# HT32F275x register map
File version: 1.1
CPU: CM3 r2p0, little endian, no MPU, no FPU, 4 interrupt priority bits
Registers are 32-bit, read-write, reset 0x0 unless marked. A register's access mark holds for its fields unless they carry their own. Offsets are from the block's base; [hi:lo] are bit positions; {n}, {i} and the like mark numbered series.

## SCI
Base 0x40043000
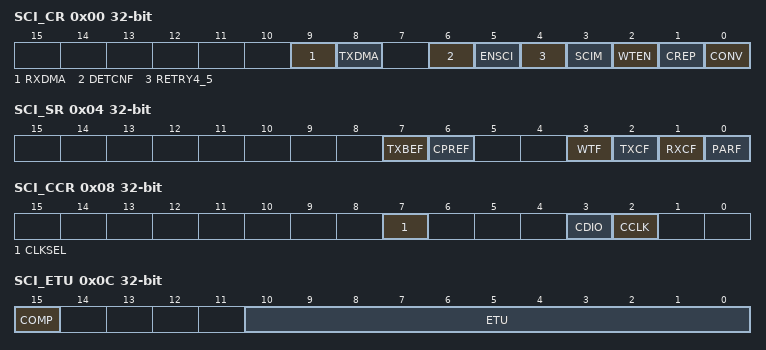
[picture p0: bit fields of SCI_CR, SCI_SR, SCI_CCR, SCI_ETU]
0x00 SCI_CR
  [9] RXDMA, [8] TXDMA, [6] DETCNF, [5] ENSCI, [4] RETRY4_5, [3] SCIM, [2] WTEN, [1] CREP, [0] CONV
0x04 SCI_SR
  [7] TXBEF, [6] CPREF, [3] WTF, [2] TXCF, [1] RXCF, [0] PARF
0x08 SCI_CCR
  [7] CLKSEL, [3] CDIO, [2] CCLK
0x0C SCI_ETU
  [15] COMP, [10:0] ETU
0x10 SCI_GT
  [8:0] GT
0x14 SCI_WT
  [23:0] WT
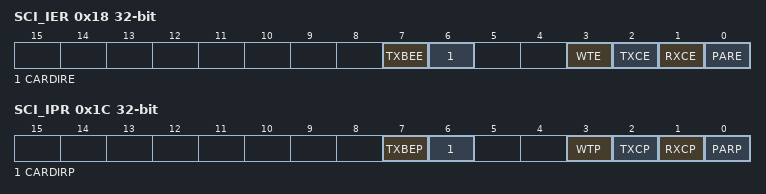
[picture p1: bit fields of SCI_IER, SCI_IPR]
0x18 SCI_IER
  [7] TXBEE, [6] CARDIRE, [3] WTE, [2] TXCE, [1] RXCE, [0] PARE
0x1C SCI_IPR
  [7] TXBEP, [6] CARDIRP, [3] WTP, [2] TXCP, [1] RXCP, [0] PARP
0x20 SCI_TXB
  [7:0] TB
0x24 SCI_RXB
  [7:0] RB
0x28 SCI_PSC
  [5:0] PSC

## USB
Base 0x4004E000
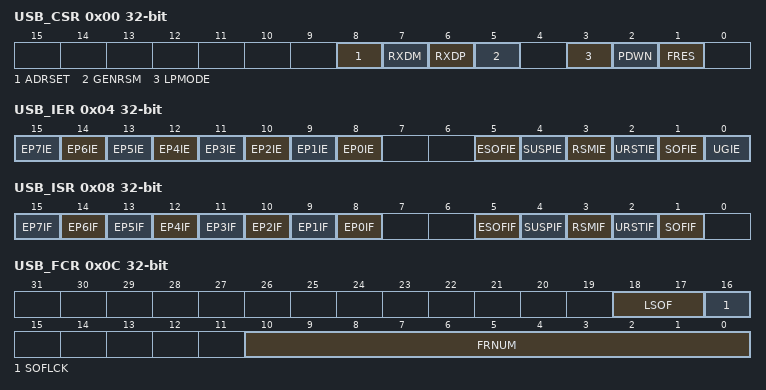
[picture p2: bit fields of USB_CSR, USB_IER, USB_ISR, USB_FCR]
0x00 USB_CSR
  [8] ADRSET, [7] RXDM, [6] RXDP, [5] GENRSM, [3] LPMODE, [2] PDWN, [1] FRES
0x04 USB_IER
  [n+8] EP{n}IE (n=0..7), [5] ESOFIE, [4] SUSPIE, [3] RSMIE, [2] URSTIE, [1] SOFIE, [0] UGIE
0x08 USB_ISR
  [n+8] EP{n}IF (n=0..7), [5] ESOFIF, [4] SUSPIF, [3] RSMIF, [2] URSTIF, [1] SOFIF
0x0C USB_FCR
  [18:17] LSOF, [16] SOFLCK, [10:0] FRNUM
0x10 USB_DEVAR
  [6:0] DEVA
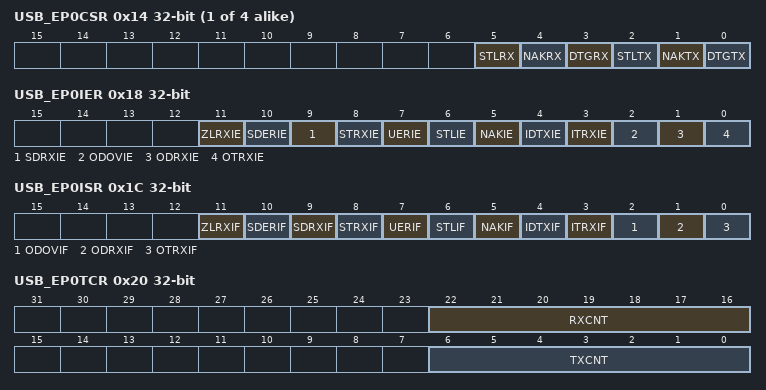
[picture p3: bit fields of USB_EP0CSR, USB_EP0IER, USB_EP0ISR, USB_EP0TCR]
{0x14+0x14*i} USB_EP{i}CSR (i=0..3)
  [5] STLRX, [4] NAKRX, [3] DTGRX, [2] STLTX, [1] NAKTX, [0] DTGTX
0x18 USB_EP0IER
  [11] ZLRXIE, [10] SDERIE, [9] SDRXIE, [8] STRXIE, [7] UERIE, [6] STLIE, [5] NAKIE, [4] IDTXIE, [3] ITRXIE, [2] ODOVIE, [1] ODRXIE, [0] OTRXIE
0x1C USB_EP0ISR
  [11] ZLRXIF, [10] SDERIF, [9] SDRXIF, [8] STRXIF, [7] UERIF, [6] STLIF, [5] NAKIF, [4] IDTXIF, [3] ITRXIF, [2] ODOVIF, [1] ODRXIF, [0] OTRXIF
0x20 USB_EP0TCR
  [22:16] RXCNT, [6:0] TXCNT
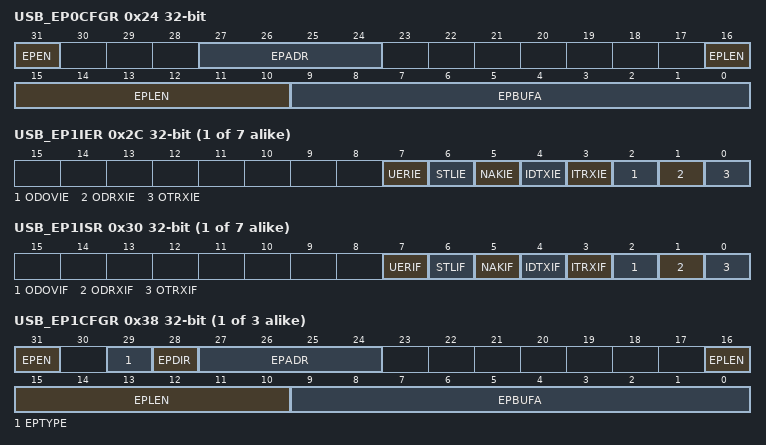
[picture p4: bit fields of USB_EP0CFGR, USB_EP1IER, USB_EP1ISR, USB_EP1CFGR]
0x24 USB_EP0CFGR
  [31] EPEN, [27:24] EPADR, [16:10] EPLEN, [9:0] EPBUFA
{0x18+0x14*i} USB_EP{i}IER (i=1..7)
  [7] UERIE, [6] STLIE, [5] NAKIE, [4] IDTXIE, [3] ITRXIE, [2] ODOVIE, [1] ODRXIE, [0] OTRXIE
{0x1C+0x14*i} USB_EP{i}ISR (i=1..7)
  [7] UERIF, [6] STLIF, [5] NAKIF, [4] IDTXIF, [3] ITRXIF, [2] ODOVIF, [1] ODRXIF, [0] OTRXIF
{0x20+0x14*i} USB_EP{i}TCR (i=1..3)
  [8:0] TCNT
{0x24+0x14*i} USB_EP{i}CFGR (i=1..3)
  [31] EPEN, [29] EPTYPE, [28] EPDIR, [27:24] EPADR, [16:10] EPLEN, [9:0] EPBUFA
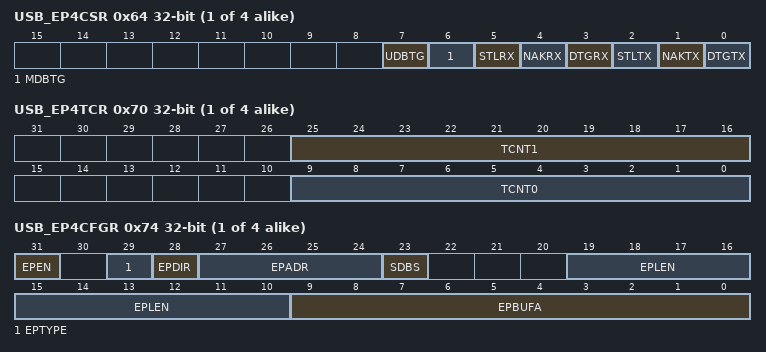
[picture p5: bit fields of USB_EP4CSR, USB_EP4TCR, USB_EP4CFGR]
{0x14+0x14*i} USB_EP{i}CSR (i=4..7)
  [7] UDBTG, [6] MDBTG, [5] STLRX, [4] NAKRX, [3] DTGRX, [2] STLTX, [1] NAKTX, [0] DTGTX
{0x20+0x14*i} USB_EP{i}TCR (i=4..7)
  [25:16] TCNT1, [9:0] TCNT0
{0x24+0x14*i} USB_EP{i}CFGR (i=4..7)
  [31] EPEN, [29] EPTYPE, [28] EPDIR, [27:24] EPADR, [23] SDBS, [19:10] EPLEN, [9:0] EPBUFA

## PDMA
Base 0x40090000
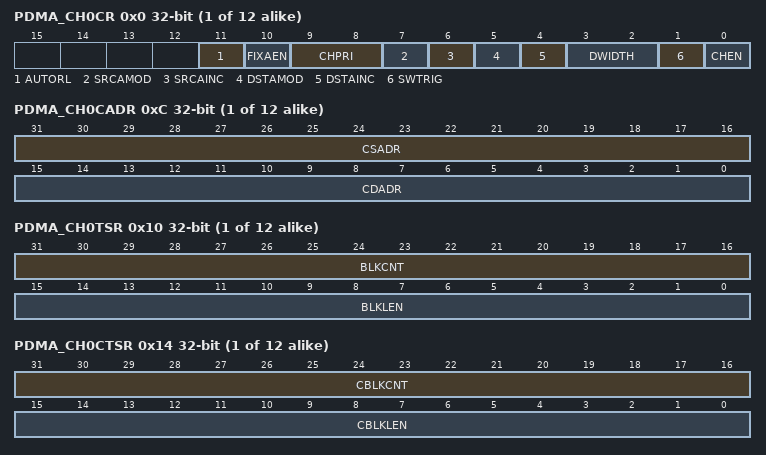
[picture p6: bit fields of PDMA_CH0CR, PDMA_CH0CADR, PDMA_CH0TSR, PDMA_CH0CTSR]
{0x0+0x18*i} PDMA_CH{i}CR (i=0..11)
  [11] AUTORL, [10] FIXAEN, [9:8] CHPRI, [7] SRCAMOD, [6] SRCAINC, [5] DSTAMOD, [4] DSTAINC, [3:2] DWIDTH, [1] SWTRIG, [0] CHEN
{0x4+0x18*i} PDMA_CH{i}SADR (i=0..11)
  [31:0] SADR
{0x8+0x18*i} PDMA_CH{i}DADR (i=0..11)
  [31:0] DADR
{0xC+0x18*i} PDMA_CH{i}CADR (i=0..11)
  [31:16] CSADR, [15:0] CDADR
{0x10+0x18*i} PDMA_CH{i}TSR (i=0..11)
  [31:16] BLKCNT, [15:0] BLKLEN
{0x14+0x18*i} PDMA_CH{i}CTSR (i=0..11)
  [31:16] CBLKCNT, [15:0] CBLKLEN
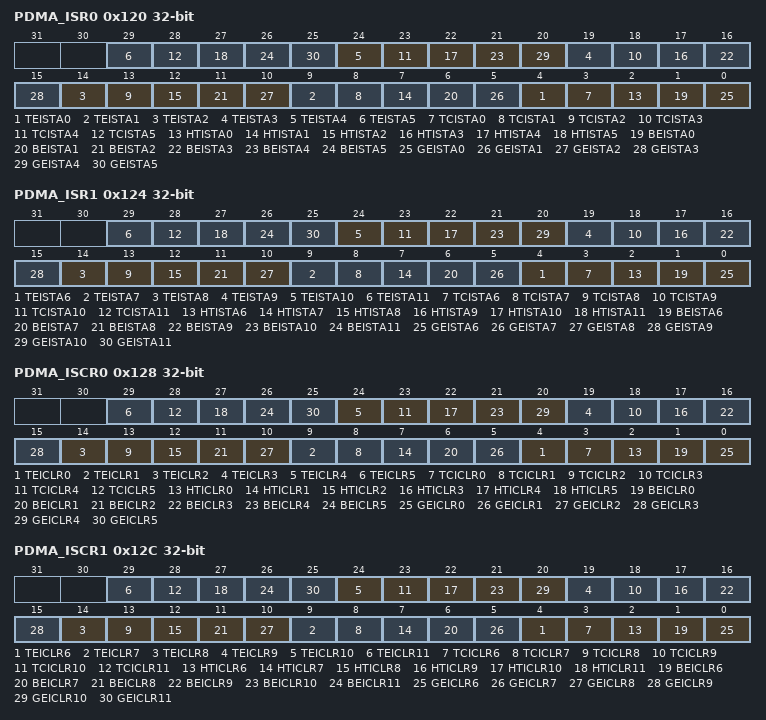
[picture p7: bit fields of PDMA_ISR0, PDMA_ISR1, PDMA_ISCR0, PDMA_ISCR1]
0x120 PDMA_ISR0
  [5n+4] TEISTA{n} (n=0..5), [5n+3] TCISTA{n} (n=0..5), [5n+2] HTISTA{n} (n=0..5), [5n+1] BEISTA{n} (n=0..5), [5n] GEISTA{n} (n=0..5)
0x124 PDMA_ISR1
  [5n-26] TEISTA{n} (n=6..11), [5n-27] TCISTA{n} (n=6..11), [5n-28] HTISTA{n} (n=6..11), [5n-29] BEISTA{n} (n=6..11), [5n-30] GEISTA{n} (n=6..11)
0x128 PDMA_ISCR0
  [5n+4] TEICLR{n} (n=0..5), [5n+3] TCICLR{n} (n=0..5), [5n+2] HTICLR{n} (n=0..5), [5n+1] BEICLR{n} (n=0..5), [5n] GEICLR{n} (n=0..5)
0x12C PDMA_ISCR1
  [5n-26] TEICLR{n} (n=6..11), [5n-27] TCICLR{n} (n=6..11), [5n-28] HTICLR{n} (n=6..11), [5n-29] BEICLR{n} (n=6..11), [5n-30] GEICLR{n} (n=6..11)
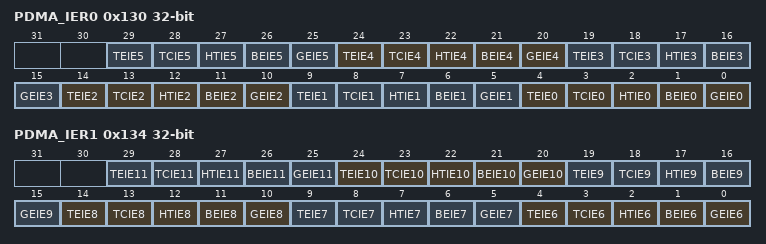
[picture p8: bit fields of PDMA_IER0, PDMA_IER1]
0x130 PDMA_IER0
  [5n+4] TEIE{n} (n=0..5), [5n+3] TCIE{n} (n=0..5), [5n+2] HTIE{n} (n=0..5), [5n+1] BEIE{n} (n=0..5), [5n] GEIE{n} (n=0..5)
0x134 PDMA_IER1
  [5n-26] TEIE{n} (n=6..11), [5n-27] TCIE{n} (n=6..11), [5n-28] HTIE{n} (n=6..11), [5n-29] BEIE{n} (n=6..11), [5n-30] GEIE{n} (n=6..11)

## CSIF
Base 0x400CC000
0x00 CSIF_ENR
  [31] CSIF_EN
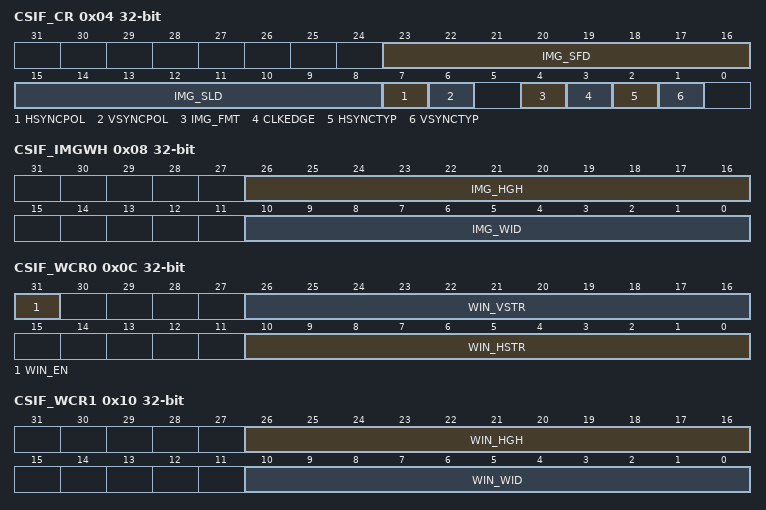
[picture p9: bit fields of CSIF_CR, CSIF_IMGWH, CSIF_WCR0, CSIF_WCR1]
0x04 CSIF_CR
  [23:16] IMG_SFD, [15:8] IMG_SLD, [7] HSYNCPOL, [6] VSYNCPOL, [4] IMG_FMT, [3] CLKEDGE, [2] HSYNCTYP, [1] VSYNCTYP
0x08 CSIF_IMGWH
  [26:16] IMG_HGH, [10:0] IMG_WID
0x0C CSIF_WCR0
  [31] WIN_EN, [26:16] WIN_VSTR, [10:0] WIN_HSTR
0x10 CSIF_WCR1
  [26:16] WIN_HGH, [10:0] WIN_WID
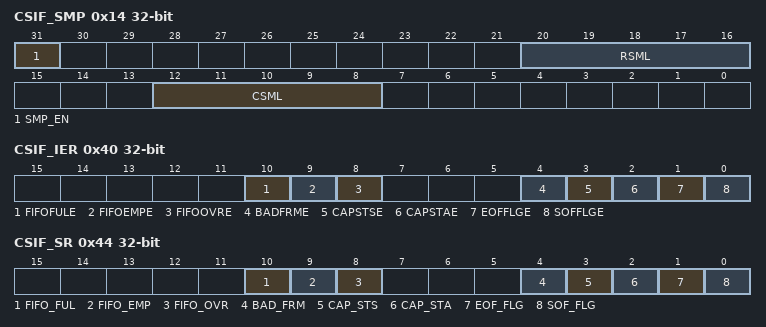
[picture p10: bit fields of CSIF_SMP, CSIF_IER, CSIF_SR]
0x14 CSIF_SMP
  [31] SMP_EN, [20:16] RSML, [12:8] CSML
0x18 CSIF_SMPCOL
  [31:0] CSM
0x1C CSIF_SMPROW
  [31:0] RSM
{0x20+4i} CSIF_FIFO{i} (i=0..7)
  [31:0] FIFODATA
0x40 CSIF_IER
  [10] FIFOFULE, [9] FIFOEMPE, [8] FIFOOVRE, [4] BADFRME, [3] CAPSTSE, [2] CAPSTAE, [1] EOFFLGE, [0] SOFFLGE
0x44 CSIF_SR
  [10] FIFO_FUL, [9] FIFO_EMP, [8] FIFO_OVR, [4] BAD_FRM, [3] CAP_STS, [2] CAP_STA, [1] EOF_FLG, [0] SOF_FLG

## Notices in the file
Copyright (C) 2010 ARM Limited. All rights reserved.
ARM Limited (ARM) is supplying this SVD description for use with Cortex-M3
processor based microcontrollers.  This file and or content can be freely
distributed within development tools that are supporting such ARM based
processors.
THIS SOFTWARE IS PROVIDED "AS IS".  NO WARRANTIES, WHETHER EXPRESS, IMPLIED
OR STATUTORY, INCLUDING, BUT NOT LIMITED TO, IMPLIED WARRANTIES OF
MERCHANTABILITY AND FITNESS FOR A PARTICULAR PURPOSE APPLY TO THIS SOFTWARE.
ARM SHALL NOT, IN ANY CIRCUMSTANCES, BE LIABLE FOR SPECIAL, INCIDENTAL, OR
CONSEQUENTIAL DAMAGES, FOR ANY REASON WHATSOEVER.
